# STM32MP21_CA35 register map
File version: 0.4
CPU: CM33 r0p1, little endian, MPU, FPU, vendor SysTick, 8 interrupt priority bits
Registers are 32-bit, read-write, reset 0x0 unless marked. A register's access mark holds for its fields unless they carry their own. Offsets are from the block's base; [hi:lo] are bit positions; lines under a group give offsets from that group; {n}, {i} and the like mark numbered series; 'fields as' and 'values as' point back to an identical list.

## DDRPHYC (part 1 of 2) — DDRPHYC address block description
Base 0x48C00000
Same registers: DDRPHYC_S 0x58C00000
{0x68+0x4000*i} DDRPHYC_ANIB{i}_MTESTMUXSEL (i=0..7) — DDRPHYC MtestMuxSel register
  [5:0] MTESTMUXSEL — Controls for the 64-1 mux for asynchronous data to the digital observation pin.
    0=Drives 0 from this chiplet (allows flat OR of pass-through information); 32=Drives 0 from PUB synthesized logic path into mux
{0x9C+0x4000*i} DDRPHYC_ANIB{i}_AFORCEDRVCONT (i=0..7) — DDRPHYC AForceDrvCont register
  [3:0] AFORCEDRVCONT — Forces continuous drive, per-lane, of the ACX4 instance controlled by this register.
{0xA0+0x4000*i} DDRPHYC_ANIB{i}_AFORCETRICONT (i=0..7) — DDRPHYC AForceTriCont register
  [3:0] AFORCETRICONT — Forces tristate control, per-lane, of the ACX4 instance controlled by this register.
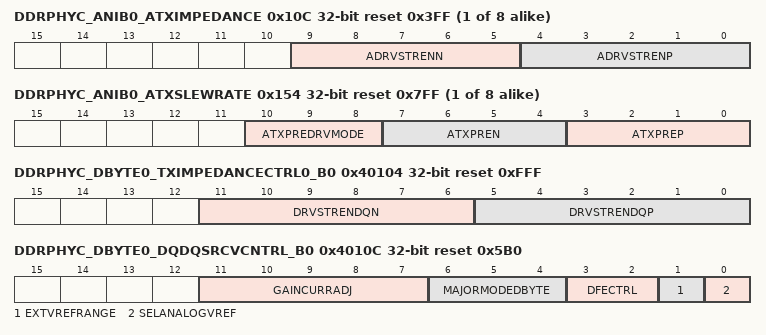
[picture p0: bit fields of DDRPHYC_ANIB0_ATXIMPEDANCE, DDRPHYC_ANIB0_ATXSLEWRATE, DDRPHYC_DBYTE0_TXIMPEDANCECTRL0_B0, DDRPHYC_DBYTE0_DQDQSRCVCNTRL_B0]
{0x10C+0x4000*i} DDRPHYC_ANIB{i}_ATXIMPEDANCE reset 0x3FF (i=0..7) — DDRPHYC address T{i} impedance control register
  [9:5] ADRVSTRENN — 5-bit bus used to select the target pull-down output impedance
    0=120; 1=60; 3=40; 7=30; 15=24; 31=20
  [4:0] ADRVSTRENP — 5-bit bus used to select the target pull-up output impedance
    0=120; 1=60; 3=40; 7=30; 15=24; 31=20
{0x14C+0x4000*i} DDRPHYC_ANIB{i}_ATESTPRBSERR ro reset not defined (i=0..7) — DDRPHYC ATestPrbsErr register
  [3:0] ATESTPRBSERR — Overall error indicator for each PRBS bump checker
{0x154+0x4000*i} DDRPHYC_ANIB{i}_ATXSLEWRATE reset 0x7FF (i=0..7) — DDRPHYC address T{i} slew rate and predriver control register
  [10:8] ATXPREDRVMODE — Controls predrivers to adjust timing of turn-on/-off of pull-up/-down segments.
  [7:4] ATXPREN — 4-bit binary trim for the driver pull-down slew rate
  [3:0] ATXPREP — 4-bit binary trim for the driver pull-up slew rate
{0x158+0x4000*i} DDRPHYC_ANIB{i}_ATESTPRBSERRCNT ro reset not defined (i=0..7) — DDRPHYC ATestPrbsErrCnt register
  [15:0] ATESTPRBSERRCNT — Overall error indicator for each PRBS bump checker
{0x200+0x4000*i} DDRPHYC_ANIB{i}_ATXDLY (i=0..7) — DDRPHYC ATxDly register
  [6:0] ATXDLY — Trained for LPDDR4 to generate timed address and command signals
0x40000 DDRPHYC_DBYTE0_DBYTEMISCMODE — DDRPHYC DBYTE module disable register
  [2] DBYTEDISABLE
    0=DBYTE enabled; 1=DBYTE disabled
0x40068 DDRPHYC_DBYTE0_MTESTMUXSEL — DDRPHYC MtestMuxSel register
  [5:0] MTESTMUXSEL — Controls for the 64-1 mux for asynchronous data to the digital observation pin.
    0=Drives 0 from this chiplet (allows flat 'OR' of pass-through information); 32=Drives 0 from PUB synthesized logic path into mux
0x40080 DDRPHYC_DBYTE0_DFIMRL reset 0x6 — DDRPHYC DFIMRL register
  [4:0] DFIMRL — DFI maximum read latency (MRL)
{0x40100+0x400*i} DDRPHYC_DBYTE0_VREFDAC0_R{i} (i=0..8) — DDRPHYC VrefDAC0_ry register
  [6:0] VREFDAC0 — PHY Rx Vless thansub>REFless than/sub> DAC control for rxdq cell internal Vless thansub>REFless than/sub>
0x40104 DDRPHYC_DBYTE0_TXIMPEDANCECTRL0_B0 reset 0xFFF — DDRPHYC data T0 impedance controls register
  [11:6] DRVSTRENDQN — 6-bit bus used to select the target pull-down output impedance
  [5:0] DRVSTRENDQP — 6-bit bus used to select the target pull-down output impedance
    0=HiZ; 1=480; 2=240; 3=160; 8=120; 9=96; 10=80; 11=68; 24=60; 25=53; 26=48; 27=43; 56=40; 57=36; 58=34; 59=32; 62=30; 63=28
0x4010C DDRPHYC_DBYTE0_DQDQSRCVCNTRL_B0 reset 0x5B0 — DDRPHYC DQ/DQS receiver control register
  [11:7] GAINCURRADJ — Adjusts gain current of RX amplifier stage.
  [6:4] MAJORMODEDBYTE — Selection of the major mode of operation for the receiver
    0=Input signal is terminated/referenced to Vless thansub>DDQless than/sub>/2 (or unterminated); 2=Input signal is terminated/referenced to Vless thansub>SSQ; 3=Input signal is terminated/referenced to Vless thansub>DDQless than/sub>
  [3:2] DFECTRL — Note: These settings are determined by PHY training firmware, and must not be overridden.
    0=DFE off; 1=DFE on; 2=Train DFE0 amplifier; 3=Train DFE1 amplifier
  [1] EXTVREFRANGE — Extends the range available in the local per-bit VREF generator.
  [0] SELANALOGVREF — Setting this bit forces the local per-bit Vless thansub>REFless than/sub> generator to pass the global VREFA
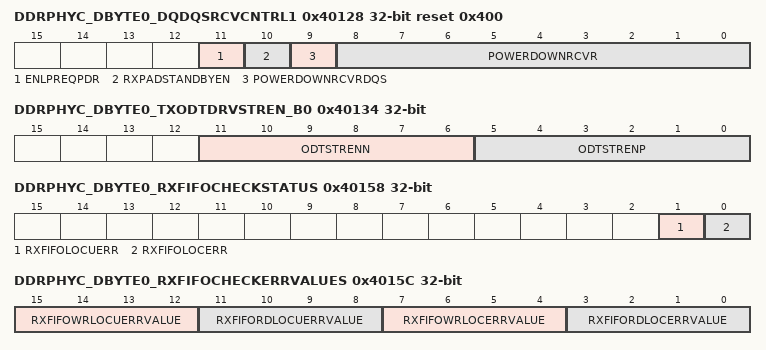
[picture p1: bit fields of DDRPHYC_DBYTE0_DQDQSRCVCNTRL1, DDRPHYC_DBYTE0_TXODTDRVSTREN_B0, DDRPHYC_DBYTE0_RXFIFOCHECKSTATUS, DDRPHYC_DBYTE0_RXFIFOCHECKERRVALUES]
0x40128 DDRPHYC_DBYTE0_DQDQSRCVCNTRL1 reset 0x400 — DDRPHYC DQ/DQS receiver control register
  [11] ENLPREQPDR — not used
  [10] RXPADSTANDBYEN — Enables rxdq/rxdqs Standby power savings, per pad-group.
  [9] POWERDOWNRCVRDQS — Active high signal which powers down the receiver
  [8:0] POWERDOWNRCVR — Active high signal which powers down the receiver
0x40130 DDRPHYC_DBYTE0_DQDQSRCVCNTRL2 — DDRPHYC DQ/DQS receiver control register
  [0] ENRXAGRESSIVEPDR
0x40134 DDRPHYC_DBYTE0_TXODTDRVSTREN_B0 — DDRPHYC TX ODT driver strength control register
  [11:6] ODTSTRENN — ODT pull-down impedance selection
  [5:0] ODTSTRENP — ODT pull-up impedance selection
0x40158 DDRPHYC_DBYTE0_RXFIFOCHECKSTATUS ro reset not defined — DDRPHYC status of RX FIFO consistency checks register
  [1] RXFIFOLOCUERR — If this bit is set, the read pointer (DFI side) on the read FIFO associated with data bits [7:4]
  [0] RXFIFOLOCERR — If this bit is set, the read pointer (DFI side) on the read FIFO associated with data bits [3:0]
0x4015C DDRPHYC_DBYTE0_RXFIFOCHECKERRVALUES ro reset not defined — DDRPHYC captured values associated with an RxFIFO consistency error register
  [15:12] RXFIFOWRLOCUERRVALUE — First error value captured for the write pointer (DQS side) on the read FIFO associated with data bits [7:4]
  [11:8] RXFIFORDLOCUERRVALUE — First error value captured for the read pointer (DFI side) on the read FIFO associated with data bits [7:4]
  [7:4] RXFIFOWRLOCERRVALUE — First error value captured for the write pointer (DQS side) on the read FIFO associated with data bits [3:0]
  [3:0] RXFIFORDLOCERRVALUE — First error value captured for the read pointer (DFI side) on the read FIFO associated with data bits [3:0]
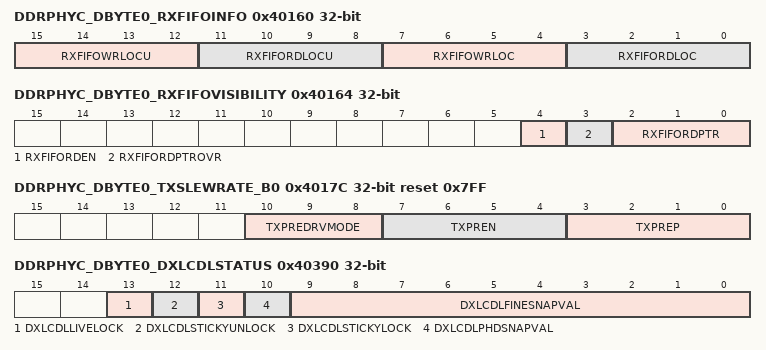
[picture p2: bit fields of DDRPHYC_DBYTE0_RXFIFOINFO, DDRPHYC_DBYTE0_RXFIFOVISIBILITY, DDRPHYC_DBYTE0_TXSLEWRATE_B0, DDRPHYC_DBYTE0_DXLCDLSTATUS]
0x40160 DDRPHYC_DBYTE0_RXFIFOINFO ro reset not defined — DDRPHYC data receive FIFO pointer values register
  [15:12] RXFIFOWRLOCU — Mission mode write pointer of the upper-nibble Rx FIFO
  [11:8] RXFIFORDLOCU — Mission mode read pointer of the upper-nibble Rx FIFO
  [7:4] RXFIFOWRLOC — Mission mode write pointer of the lower-nibble Rx FIFO
  [3:0] RXFIFORDLOC — Mission mode read pointer of the lower-nibble Rx FIFO
0x40164 DDRPHYC_DBYTE0_RXFIFOVISIBILITY — DDRPHYC R0 FIFO visibility register
  [4] RXFIFORDEN — Pulse [set 0-->1-->0] this bit to capture the FIFO contents.
  [3] RXFIFORDPTROVR — This bit is programmable as follows:
    0=Normal operation - Mission mode read pointer is enabled; 1=Override - Control of the Rx FIFO read pointer is ceded to this bit
  [2:0] RXFIFORDPTR — If RXFIFORDPTROVR is set, this bit field selects the Rx FIFO entry.
0x40168 DDRPHYC_DBYTE0_RXFIFOCONTENTSDQ3210 ro reset not defined — DDRPHYC R0 FIFO content DQ321x register
  [15:0] RXFIFOCONTENTSDQ3210 — Window into the contents of the Rx FIFO, as controlled
0x4016C DDRPHYC_DBYTE0_RXFIFOCONTENTSDQ7654 ro reset not defined — DDRPHYC R0 FIFO content DQ7654 register
  [15:0] RXFIFOCONTENTSDQ7654 — Window into the contents of the Rx FIFO as controlled
0x40170 DDRPHYC_DBYTE0_RXFIFOCONTENTSDBI ro reset not defined — DDRPHYC R0 FIFO content DBI register
  [3:0] RXFIFOCONTENTSDBI — Window into the contents of the Rx FIFO, as controlled
0x4017C DDRPHYC_DBYTE0_TXSLEWRATE_B0 reset 0x7FF — DDRPHYC T0 slew rate controls register
  [10:8] TXPREDRVMODE — Controls predrivers to adjust timing of turn-on and turn-off of pull-up and pull-down segments.
  [7:4] TXPREN — 4-bit binary trim for the driver pull -own slew rate
  [3:0] TXPREP — 4-bit binary trim for the driver pull-up slew rate
{0x401A0+0x400*i} DDRPHYC_DBYTE0_RXPBDLYTG0_R{i} (i=0..8) — DDRPHYC RxPBDlyTgx_r0 register
  [6:0] RXPBDLYTG0_R0 — Read DQ per-bit BDL delay (timing group 0)
{0x401A4+0x400*i} DDRPHYC_DBYTE0_RXPBDLYTG1_R{i} (i=0..8) — DDRPHYC RxPBDlyTg1_rx register
  [6:0] RXPBDLYTG1_R0 — Read DQ per-bit BDL delay (timing group 1)
0x40200 DDRPHYC_DBYTE0_RXENDLYTG0_U0 reset 0x100 — DDRPHYC RxEnDlyTgx_u0 register
  [10:0] RXENDLYTG0_U0 — Trained receive enable delay (timing group 0)
0x40204 DDRPHYC_DBYTE0_RXENDLYTG1_U0 reset 0x100 — DDRPHYC RxEnDlyTg1_ux register
  [10:0] RXENDLYTG1_U0 — Trained receive enable delay (timing group 1)
0x40230 DDRPHYC_DBYTE0_RXCLKDLYTG0_U0 reset 0x10 — DDRPHYC RxClkDlyTgx_u0 register
  [5:0] RXCLKDLYTG0_U0 — Trained read DQS to RxClk delay (timing group 0)
0x40234 DDRPHYC_DBYTE0_RXCLKDLYTG1_U0 reset 0x10 — DDRPHYC RxClkDlyTg1_ux register
  [5:0] RXCLKDLYTG1_U0 — Trained read DQS to RxClk delay (timing group 1)
0x40240 DDRPHYC_DBYTE0_RXCLKCDLYTG0_U0 reset 0x10 — DDRPHYC RxClkcDlyTgx_u0 register
  [5:0] RXCLKCDLYTG0_U0 — Trained read DQS_c to RxClkc delay (timing group 0)
0x40244 DDRPHYC_DBYTE0_RXCLKCDLYTG1_U0 reset 0x10 — DDRPHYC RxClkcDlyTg1_ux register
  [5:0] RXCLKCDLYTG1_U0 — Trained read DQS_c to RxClkc delay (timing group 1)
0x40280 DDRPHYC_DBYTE0_DQ0LNSEL — DDRPHYC DqLnSel register
  [2:0] DQYLNSEL — Supports mapping of PHY DQ to DRAM DQ within a byte (swizzle).
0x40284 DDRPHYC_DBYTE0_DQ1LNSEL reset 0x1 — DDRPHYC DqLnSel register
  fields as DDRPHYC_DBYTE0_DQ0LNSEL
0x40288 DDRPHYC_DBYTE0_DQ2LNSEL reset 0x2 — DDRPHYC DqLnSel register
  fields as DDRPHYC_DBYTE0_DQ0LNSEL
0x4028C DDRPHYC_DBYTE0_DQ3LNSEL reset 0x3 — DDRPHYC DqLnSel register
  fields as DDRPHYC_DBYTE0_DQ0LNSEL
0x40290 DDRPHYC_DBYTE0_DQ4LNSEL reset 0x4 — DDRPHYC DqLnSel register
  fields as DDRPHYC_DBYTE0_DQ0LNSEL
0x40294 DDRPHYC_DBYTE0_DQ5LNSEL reset 0x5 — DDRPHYC DqLnSel register
  fields as DDRPHYC_DBYTE0_DQ0LNSEL
0x40298 DDRPHYC_DBYTE0_DQ6LNSEL reset 0x6 — DDRPHYC DqLnSel register
  fields as DDRPHYC_DBYTE0_DQ0LNSEL
0x4029C DDRPHYC_DBYTE0_DQ7LNSEL reset 0x7 — DDRPHYC DqLnSel register
  fields as DDRPHYC_DBYTE0_DQ0LNSEL
{0x40300+0x400*i} DDRPHYC_DBYTE0_TXDQDLYTG0_R{i} reset 0x10 (i=0..8) — DDRPHYC TxDqDlyTgx_r0 register
  [8:0] TXDQDLYTG0_R0 — Write DQ delay (timing group 0)
{0x40304+0x400*i} DDRPHYC_DBYTE0_TXDQDLYTG1_R{i} reset 0x10 (i=0..8) — DDRPHYC TxDqDlyTg1_rx register
  [8:0] TXDQDLYTG1_R0 — Write DQ delay (timing group 1)
0x40340 DDRPHYC_DBYTE0_TXDQSDLYTG0_U0 reset 0x100 — DDRPHYC TxDqsDlyTgx_u0 register
  [9:0] TXDQSDLYTG0_U0 — Write DQS delay (timing group 0)
0x40344 DDRPHYC_DBYTE0_TXDQSDLYTG1_U0 reset 0x100 — DDRPHYC TxDqsDlyTg1_ux register
  [9:0] TXDQSDLYTG1_U0 — Write DQS delay (timing group 1)
0x40390 DDRPHYC_DBYTE0_DXLCDLSTATUS ro reset not defined — DDRPHYC debug status of the DBYTE LCDL register
  [13] DXLCDLLIVELOCK — Present value of whether the LCDL is locked
  [12] DXLCDLSTICKYUNLOCK — Latched value of whether the LCDL ever lost lock after the assertion of LCDLTSTENABLE
  [11] DXLCDLSTICKYLOCK — Latched value of whether the LCDL ever achieved lock after the assertion of LCDLTSTENABLE
  [10] DXLCDLPHDSNAPVAL — Value of the LCDL phase-detector output, latched by pulse
  [9:0] DXLCDLFINESNAPVAL — Value of the LCDL 1UI estimate code, latched by pulse on LcdlFineSnap while LCDLTSTENABLE = 1
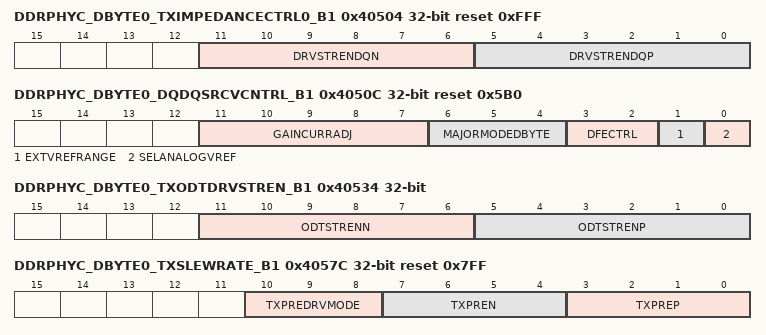
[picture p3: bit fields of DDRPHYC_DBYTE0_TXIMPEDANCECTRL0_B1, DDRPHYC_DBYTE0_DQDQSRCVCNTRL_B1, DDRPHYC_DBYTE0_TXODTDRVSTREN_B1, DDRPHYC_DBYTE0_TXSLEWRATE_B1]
0x40504 DDRPHYC_DBYTE0_TXIMPEDANCECTRL0_B1 reset 0xFFF — DDRPHYC data T0 impedance controls register
  fields as DDRPHYC_DBYTE0_TXIMPEDANCECTRL0_B0
0x4050C DDRPHYC_DBYTE0_DQDQSRCVCNTRL_B1 reset 0x5B0 — DDRPHYC DQ/DQS receiver control register
  fields as DDRPHYC_DBYTE0_DQDQSRCVCNTRL_B0
0x40534 DDRPHYC_DBYTE0_TXODTDRVSTREN_B1 — DDRPHYC TX ODT driver strength control register
  fields as DDRPHYC_DBYTE0_TXODTDRVSTREN_B0
0x4057C DDRPHYC_DBYTE0_TXSLEWRATE_B1 reset 0x7FF — DDRPHYC T0 slew rate controls register
  fields as DDRPHYC_DBYTE0_TXSLEWRATE_B0
0x40600 DDRPHYC_DBYTE0_RXENDLYTG0_U1 reset 0x100 — DDRPHYC RxEnDlyTgx_u1 register
  [10:0] RXENDLYTG0_U1 — Trained receive enable delay (timing group 0)
0x40604 DDRPHYC_DBYTE0_RXENDLYTG1_U1 reset 0x100 — DDRPHYC RxEnDlyTg1_u1 register
  [10:0] RXENDLYTG1_U1 — Trained receive enable delay (timing group 1)
0x40630 DDRPHYC_DBYTE0_RXCLKDLYTG0_U1 reset 0x10 — DDRPHYC RxClkDlyTgx_u1 register
  [5:0] RXCLKDLYTG0_U1 — Trained read DQS to RxClk delay (timing group 0)
0x40634 DDRPHYC_DBYTE0_RXCLKDLYTG1_U1 reset 0x10 — DDRPHYC RxClkDlyTg1_u1 register
  [5:0] RXCLKDLYTG1_U1 — Trained read DQS to RxClk delay (timing group 1)
0x40640 DDRPHYC_DBYTE0_RXCLKCDLYTG0_U1 reset 0x10 — DDRPHYC RxClkcDlyTgx_u1 register
  [5:0] RXCLKCDLYTG0_U1 — Trained read DQS_c to RxClkc delay (timing group 0)
0x40644 DDRPHYC_DBYTE0_RXCLKCDLYTG1_U1 reset 0x10 — DDRPHYC RxClkcDlyTg1_u1 register
  [5:0] RXCLKCDLYTG1_U1 — Trained read DQS_c to RxClkc delay (timing group 1)
0x40740 DDRPHYC_DBYTE0_TXDQSDLYTG0_U1 reset 0x100 — DDRPHYC TxDqsDlyTgx_u1 register
  [9:0] TXDQSDLYTG0_U1 — Write DQS delay (timing group 0)
0x40744 DDRPHYC_DBYTE0_TXDQSDLYTG1_U1 reset 0x100 — DDRPHYC TxDqsDlyTg1_u1 register
  [9:0] TXDQSDLYTG1_U1 — Write DQS delay (timing group 1)
0x44000 DDRPHYC_DBYTE1_DBYTEMISCMODE — DDRPHYC DBYTE module disable register
  [2] DBYTEDISABLE
    0=DBYTE enabled; 1=DBYTE disabled
0x44068 DDRPHYC_DBYTE1_MTESTMUXSEL — DDRPHYC MtestMuxSel register
  fields as DDRPHYC_DBYTE0_MTESTMUXSEL
0x44080 DDRPHYC_DBYTE1_DFIMRL reset 0x6 — DDRPHYC DFIMRL register
  [4:0] DFIMRL — DFI maximum read latency (MRL)
{0x44100+0x400*i} DDRPHYC_DBYTE1_VREFDAC0_R{i} (i=0..8) — DDRPHYC VrefDAC0_ry register
  fields as DDRPHYC_DBYTE0_VREFDAC0_R0
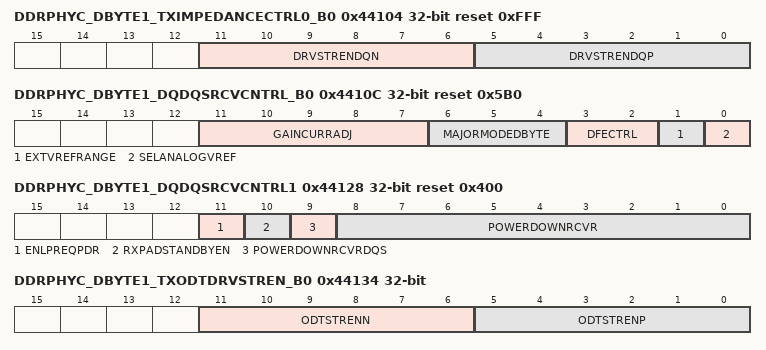
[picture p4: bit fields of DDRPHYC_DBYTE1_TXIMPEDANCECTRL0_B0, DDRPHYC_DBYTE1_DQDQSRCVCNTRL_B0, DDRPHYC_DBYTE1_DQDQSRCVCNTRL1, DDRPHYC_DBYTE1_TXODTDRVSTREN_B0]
0x44104 DDRPHYC_DBYTE1_TXIMPEDANCECTRL0_B0 reset 0xFFF — DDRPHYC data T1 impedance controls register
  fields as DDRPHYC_DBYTE0_TXIMPEDANCECTRL0_B0
0x4410C DDRPHYC_DBYTE1_DQDQSRCVCNTRL_B0 reset 0x5B0 — DDRPHYC DQ/DQS receiver control register
  fields as DDRPHYC_DBYTE0_DQDQSRCVCNTRL_B0
0x44128 DDRPHYC_DBYTE1_DQDQSRCVCNTRL1 reset 0x400 — DDRPHYC DQ/DQS receiver control register
  fields as DDRPHYC_DBYTE0_DQDQSRCVCNTRL1
0x44130 DDRPHYC_DBYTE1_DQDQSRCVCNTRL2 — DDRPHYC DQ/DQS receiver control register
  [0] ENRXAGRESSIVEPDR
0x44134 DDRPHYC_DBYTE1_TXODTDRVSTREN_B0 — DDRPHYC TX ODT driver strength control register
  fields as DDRPHYC_DBYTE0_TXODTDRVSTREN_B0
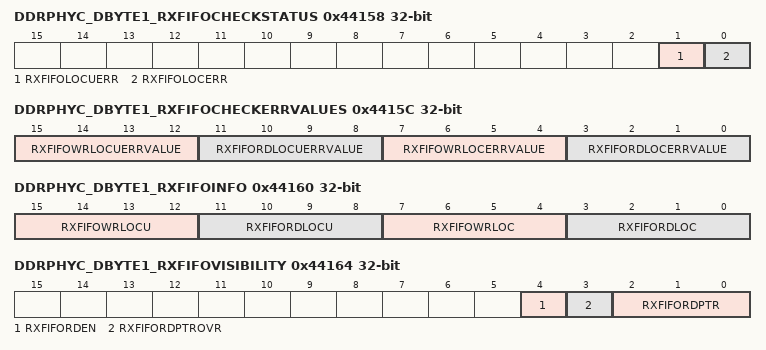
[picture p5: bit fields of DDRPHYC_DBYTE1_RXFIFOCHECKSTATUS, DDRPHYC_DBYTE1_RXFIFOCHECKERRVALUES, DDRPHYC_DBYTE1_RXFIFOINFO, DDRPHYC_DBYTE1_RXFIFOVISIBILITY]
0x44158 DDRPHYC_DBYTE1_RXFIFOCHECKSTATUS ro reset not defined — DDRPHYC status of RX FIFO consistency checks register
  fields as DDRPHYC_DBYTE0_RXFIFOCHECKSTATUS
0x4415C DDRPHYC_DBYTE1_RXFIFOCHECKERRVALUES ro reset not defined — DDRPHYC captured values associated with an RxFIFO consistency error register
  fields as DDRPHYC_DBYTE0_RXFIFOCHECKERRVALUES
0x44160 DDRPHYC_DBYTE1_RXFIFOINFO ro reset not defined — DDRPHYC data receive FIFO pointer values register
  fields as DDRPHYC_DBYTE0_RXFIFOINFO
0x44164 DDRPHYC_DBYTE1_RXFIFOVISIBILITY — DDRPHYC R1 FIFO visibility register
  fields as DDRPHYC_DBYTE0_RXFIFOVISIBILITY
0x44168 DDRPHYC_DBYTE1_RXFIFOCONTENTSDQ3210 ro reset not defined — DDRPHYC R1 FIFO content DQ321x register
  fields as DDRPHYC_DBYTE0_RXFIFOCONTENTSDQ3210
0x4416C DDRPHYC_DBYTE1_RXFIFOCONTENTSDQ7654 ro reset not defined — DDRPHYC R1 FIFO content DQ7654 register
  fields as DDRPHYC_DBYTE0_RXFIFOCONTENTSDQ7654
0x44170 DDRPHYC_DBYTE1_RXFIFOCONTENTSDBI ro reset not defined — DDRPHYC R1 FIFO content DBI register
  fields as DDRPHYC_DBYTE0_RXFIFOCONTENTSDBI
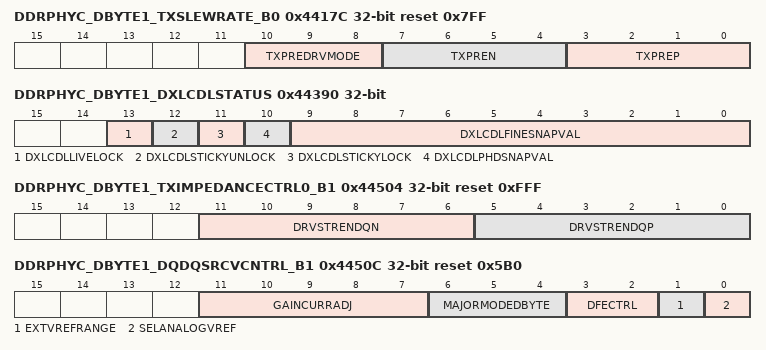
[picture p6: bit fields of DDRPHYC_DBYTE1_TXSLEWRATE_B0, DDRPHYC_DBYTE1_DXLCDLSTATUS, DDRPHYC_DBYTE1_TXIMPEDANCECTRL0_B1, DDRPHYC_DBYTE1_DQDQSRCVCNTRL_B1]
0x4417C DDRPHYC_DBYTE1_TXSLEWRATE_B0 reset 0x7FF — DDRPHYC T1 slew rate controls register
  fields as DDRPHYC_DBYTE0_TXSLEWRATE_B0
{0x441A0+0x400*i} DDRPHYC_DBYTE1_RXPBDLYTG0_R{i} (i=0..8) — DDRPHYC RxPBDlyTgx_r0 register
  [6:0] RXPBDLYTG0_R0 — Read DQ per-bit BDL delay (timing group 0)
{0x441A4+0x400*i} DDRPHYC_DBYTE1_RXPBDLYTG1_R{i} (i=0..8) — DDRPHYC RxPBDlyTg1_rx register
  [6:0] RXPBDLYTG1_R0 — Read DQ per-bit BDL delay (timing group 1)
0x44200 DDRPHYC_DBYTE1_RXENDLYTG0_U0 reset 0x100 — DDRPHYC RxEnDlyTgx_u0 register
  [10:0] RXENDLYTG0_U0 — Trained receive enable delay (timing group 0)
0x44204 DDRPHYC_DBYTE1_RXENDLYTG1_U0 reset 0x100 — DDRPHYC RxEnDlyTg1_ux register
  [10:0] RXENDLYTG1_U0 — Trained receive enable delay (timing group 1)
0x44230 DDRPHYC_DBYTE1_RXCLKDLYTG0_U0 reset 0x10 — DDRPHYC RxClkDlyTgx_u0 register
  fields as DDRPHYC_DBYTE0_RXCLKDLYTG0_U0
0x44234 DDRPHYC_DBYTE1_RXCLKDLYTG1_U0 reset 0x10 — DDRPHYC RxClkDlyTg1_ux register
  fields as DDRPHYC_DBYTE0_RXCLKDLYTG1_U0
0x44240 DDRPHYC_DBYTE1_RXCLKCDLYTG0_U0 reset 0x10 — DDRPHYC RxClkcDlyTgx_u0 register
  fields as DDRPHYC_DBYTE0_RXCLKCDLYTG0_U0
0x44244 DDRPHYC_DBYTE1_RXCLKCDLYTG1_U0 reset 0x10 — DDRPHYC RxClkcDlyTg1_ux register
  fields as DDRPHYC_DBYTE0_RXCLKCDLYTG1_U0
{0x44280+4i} DDRPHYC_DBYTE1_DQ{i}LNSEL reset 0x7 (i=0..7) — DDRPHYC DqLnSel register
  fields as DDRPHYC_DBYTE0_DQ0LNSEL
{0x44300+0x400*i} DDRPHYC_DBYTE1_TXDQDLYTG0_R{i} reset 0x10 (i=0..8) — DDRPHYC TxDqDlyTgx_r0 register
  [8:0] TXDQDLYTG0_R0 — Write DQ delay (timing group 0)
{0x44304+0x400*i} DDRPHYC_DBYTE1_TXDQDLYTG1_R{i} reset 0x10 (i=0..8) — DDRPHYC TxDqDlyTg1_rx register
  [8:0] TXDQDLYTG1_R0 — Write DQ delay (timing group 1)
0x44340 DDRPHYC_DBYTE1_TXDQSDLYTG0_U0 reset 0x100 — DDRPHYC TxDqsDlyTgx_u0 register
  [9:0] TXDQSDLYTG0_U0 — Write DQS delay (timing group 0)
0x44344 DDRPHYC_DBYTE1_TXDQSDLYTG1_U0 reset 0x100 — DDRPHYC TxDqsDlyTg1_ux register
  [9:0] TXDQSDLYTG1_U0 — Write DQS delay (timing group 1)
0x44390 DDRPHYC_DBYTE1_DXLCDLSTATUS ro reset not defined — DDRPHYC debug status of the DBYTE LCDL register
  fields as DDRPHYC_DBYTE0_DXLCDLSTATUS
0x44504 DDRPHYC_DBYTE1_TXIMPEDANCECTRL0_B1 reset 0xFFF — DDRPHYC data T1 impedance controls register
  fields as DDRPHYC_DBYTE0_TXIMPEDANCECTRL0_B0
0x4450C DDRPHYC_DBYTE1_DQDQSRCVCNTRL_B1 reset 0x5B0 — DDRPHYC DQ/DQS receiver control register
  fields as DDRPHYC_DBYTE0_DQDQSRCVCNTRL_B0
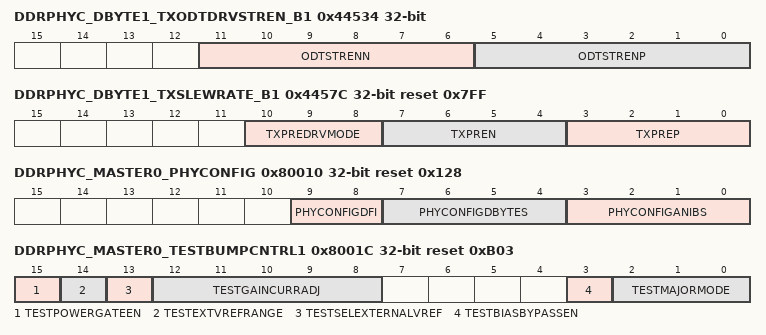
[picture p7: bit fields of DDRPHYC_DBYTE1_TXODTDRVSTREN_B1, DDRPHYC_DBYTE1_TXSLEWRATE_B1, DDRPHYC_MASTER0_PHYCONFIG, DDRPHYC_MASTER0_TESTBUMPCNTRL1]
0x44534 DDRPHYC_DBYTE1_TXODTDRVSTREN_B1 — DDRPHYC TX ODT driver strength control register
  fields as DDRPHYC_DBYTE0_TXODTDRVSTREN_B0
0x4457C DDRPHYC_DBYTE1_TXSLEWRATE_B1 reset 0x7FF — DDRPHYC T1 slew rate controls register
  fields as DDRPHYC_DBYTE0_TXSLEWRATE_B0
0x44600 DDRPHYC_DBYTE1_RXENDLYTG0_U1 reset 0x100 — DDRPHYC RxEnDlyTgx_u1 register
  [10:0] RXENDLYTG0_U1 — Trained receive enable delay (timing group 0)
0x44604 DDRPHYC_DBYTE1_RXENDLYTG1_U1 reset 0x100 — DDRPHYC RxEnDlyTg1_u1 register
  [10:0] RXENDLYTG1_U1 — Trained receive enable delay (timing group 1)
0x44630 DDRPHYC_DBYTE1_RXCLKDLYTG0_U1 reset 0x10 — DDRPHYC RxClkDlyTgx_u1 register
  fields as DDRPHYC_DBYTE0_RXCLKDLYTG0_U1
0x44634 DDRPHYC_DBYTE1_RXCLKDLYTG1_U1 reset 0x10 — DDRPHYC RxClkDlyTg1_u1 register
  fields as DDRPHYC_DBYTE0_RXCLKDLYTG1_U1
0x44640 DDRPHYC_DBYTE1_RXCLKCDLYTG0_U1 reset 0x10 — DDRPHYC RxClkcDlyTgx_u1 register
  fields as DDRPHYC_DBYTE0_RXCLKCDLYTG0_U1
0x44644 DDRPHYC_DBYTE1_RXCLKCDLYTG1_U1 reset 0x10 — DDRPHYC RxClkcDlyTg1_u1 register
  fields as DDRPHYC_DBYTE0_RXCLKCDLYTG1_U1
0x44740 DDRPHYC_DBYTE1_TXDQSDLYTG0_U1 reset 0x100 — DDRPHYC TxDqsDlyTgx_u1 register
  [9:0] TXDQSDLYTG0_U1 — Write DQS delay (timing group 0)
0x44744 DDRPHYC_DBYTE1_TXDQSDLYTG1_U1 reset 0x100 — DDRPHYC TxDqsDlyTg1_u1 register
  [9:0] TXDQSDLYTG1_U1 — Write DQS delay (timing group 1)
0x80000 DDRPHYC_MASTER0_RXFIFOINIT — DDRPHYC Rx FIFO pointer initialization control register
  [0] RXFIFOINITPTR — Setting this bit resets the PHY RXDATAFIFO read and write pointers.
0x80004 DDRPHYC_MASTER0_FORCECLKDISABLE — DDRPHYC ForceClkDisable register
  [3:0] FORCECLKDISABLE — This bit field forces the gating of MEMCLKs driven from the PHY.
0x8000C DDRPHYC_MASTER0_FORCEINTERNALUPDATE — DDRPHYC ForceInternalUpdate register
  [0] FORCEINTERNALUPDATE — Used by training firmware to force an internal PHY update event
0x80010 DDRPHYC_MASTER0_PHYCONFIG ro reset 0x128 — DDRPHYC read-only displays PHY configuration register
  [9:8] PHYCONFIGDFI — Returns the following value depending on the define:
  [7:4] PHYCONFIGDBYTES — Returns the following value depending on the define:
  [3:0] PHYCONFIGANIBS — Returns the following value depending on the define:
0x80014 DDRPHYC_MASTER0_PGCR — DDRPHYC PHY general configuration register
  [0] RXCLKRISEFALLMODE — Controls independent training for RxClk_c and RxClk_t.
    0=Independent training for RxClk_c and RxClk_t is disabled (default value); 1=Independent training for RxClk_c and RxClk_t is enabled
0x8001C DDRPHYC_MASTER0_TESTBUMPCNTRL1 reset 0xB03 — DDRPHYC test bump control1 register
  [15] TESTPOWERGATEEN — Do not use, for debug only
  [14] TESTEXTVREFRANGE — Setting this bit extends the VREF DAC range for debug.
  [13] TESTSELEXTERNALVREF — Do not use, for debug only
  [12:8] TESTGAINCURRADJ — Adjust gain and current of analog observe RX amplifier stage at analog test point.
  [3] TESTBIASBYPASSEN — Do not use, for debug only
  [2:0] TESTMAJORMODE — Selects the major mode of operation for the receiver.
    3=Setting for DDR4 systems to receive Alert_n
0x80020 DDRPHYC_MASTER0_CALUCLKINFO reset 0x320 — DDRPHYC impedance calibration clock ratio register
  [10:0] CALUCLKTICKSPER1US — Must be programmed to the number of DfiClks in 1 us (rounded up), with minimum value
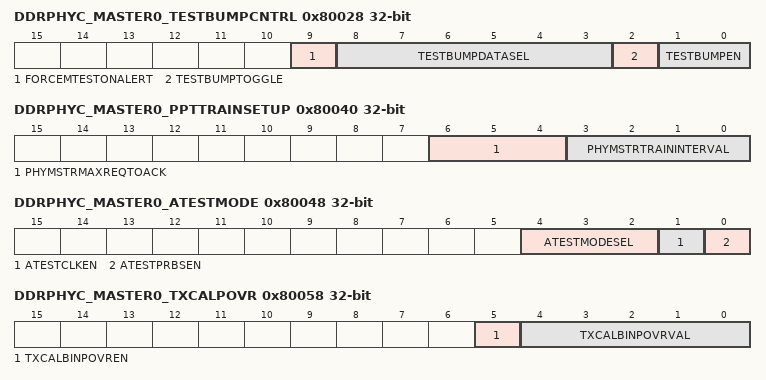
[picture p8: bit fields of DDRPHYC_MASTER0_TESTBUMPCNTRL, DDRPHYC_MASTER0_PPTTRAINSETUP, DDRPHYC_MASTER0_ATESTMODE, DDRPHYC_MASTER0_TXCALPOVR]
0x80028 DDRPHYC_MASTER0_TESTBUMPCNTRL — DDRPHYC test bump control register
  [9] FORCEMTESTONALERT — When set, this bit causes the digital observation output pin to be driven onto BP_ALERT_N.
  [8:3] TESTBUMPDATASEL — RVSD
  [2] TESTBUMPTOGGLE — Controls the output function of the signal.
    0=The output is tristate; 1=The output is selected by MtestMuxSel
  [1:0] TESTBUMPEN — Controls the output function of the signal BP_ALERT_N.
    0=High-z; 1=Pllout-divided-by-2, works up to full data rate; 2=PllDigTst[1], works up to 400 MHz; 3=PllDigTst[1], works up to 400 MHz
{0x8002C+4i} DDRPHYC_MASTER0_SEQ0BDLY{i} (i=0..3) — DDRPHYC Seq0BDLY{i} register
  [15:0] SEQ0BDLY{i} — PIE delay register {i}
0x8003C DDRPHYC_MASTER0_PHYALERTSTATUS ro reset not defined — DDRPHYC PHY alert status bit register
  [0] PHYALERT — Current state of ALERT_N
0x80040 DDRPHYC_MASTER0_PPTTRAINSETUP — DDRPHYC setup intervals for DFI PHY master operation register
  [6:4] PHYMSTRMAXREQTOACK — Max time from tdfi_phymstr_req asserted
    0=Disable PHY MASTER; {v}=Set tPHYMSTR_resp (v=1..6)
  [3:0] PHYMSTRTRAININTERVAL — Time between the end of one training, and the start
    0=Disable PHY MASTER; 1=PHY MASTER request interval = 524288 MEMCLKs; 2=PHY MASTER request interval = 1048576 MEMCLKs; 3=PHY MASTER request interval = 2097152 MEMCLKs; 4=PHY MASTER request interval = 4194304 MEMCLKs; 5=PHY MASTER request interval = 8388608 MEMCLKs; 6=PHY MASTER request interval = 16777216 MEMCLKs; 7=PHY MASTER request interval = 33554432 MEMCLKs; 8=PHY MASTER request interval = 67108864 MEMCLKs; 9=PHY MASTER request interval = 134217728 MEMCLKs; 10=PHY MASTER request interval = 268435456 MEMCLKs
0x80048 DDRPHYC_MASTER0_ATESTMODE — DDRPHYC ATestMode control register
  [4:2] ATESTMODESEL — Master mode select for ATest (loopback)
    0=Mission mode, all ATest disabled, loopback receivers powered down; 1=External loopback mode [Single data rate pattern - dfi_cas sent to all lanes]; 2=Internal loopback mode [Single data rate pattern]; 3=Internal loopback mode [Double data rate pattern]; 4=External loopback mode [Single data rate pattern - corresponding DFI signal sent to each lane]
  [1] ATESTCLKEN — Not used
  [0] ATESTPRBSEN — Enables loopback PRBS7 testing of all the DDR output pins.
0x80050 DDRPHYC_MASTER0_TXCALBINP ro reset not defined — DDRPHYC TxCalBinP register
  [4:0] TXCALBINP — Binary result of the 31-bit thermometer pull-up code
0x80054 DDRPHYC_MASTER0_TXCALBINN ro reset not defined — DDRPHYC TxCalBinN register
  [4:0] TXCALBINN — Binary result of the 31-bit thermometer pull-down code
0x80058 DDRPHYC_MASTER0_TXCALPOVR — DDRPHYC TX P impedance calibration override register
  [5] TXCALBINPOVREN
    1=Use the override value present in TxCalBinPOvrVal bit
  [4:0] TXCALBINPOVRVAL — Binary value which can override TXCALBINP bitfiled
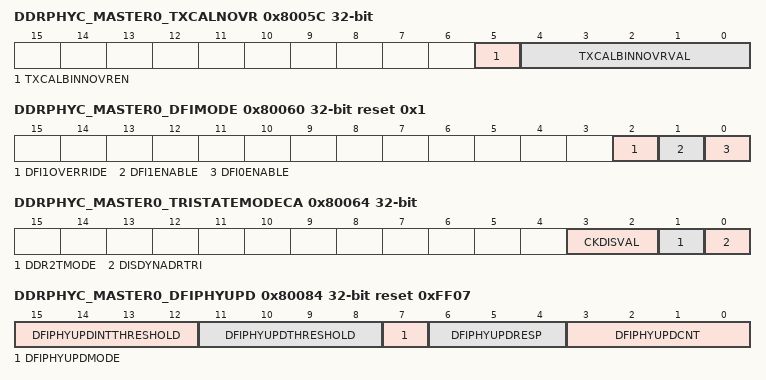
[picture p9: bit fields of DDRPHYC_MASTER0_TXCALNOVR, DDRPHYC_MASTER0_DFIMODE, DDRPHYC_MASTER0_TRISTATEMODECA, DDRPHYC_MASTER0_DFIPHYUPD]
0x8005C DDRPHYC_MASTER0_TXCALNOVR — DDRPHYC TX N impedance calibration override register
  [5] TXCALBINNOVREN
    1=Use the override value present in TXCALBINNOVRVAL bit field
  [4:0] TXCALBINNOVRVAL — Binary value which can override TXCALBINN bit field
0x80060 DDRPHYC_MASTER0_DFIMODE reset 0x1 — DDRPHYC enables for update and low-power interfaces for DFI0 and DFI1 register
  [2] DFI1OVERRIDE — Controls the PHY logic associated with both DFI0 and DFI1.
  [1] DFI1ENABLE — Enables operation for the PHY logic associated with DFI1.
  [0] DFI0ENABLE — Enables operation for the PHY logic associated with DFI0.
0x80064 DDRPHYC_MASTER0_TRISTATEMODECA — DDRPHYC mode select register for MEMCLK/address/command tristate register
  [3:2] CKDISVAL — The PHY provides four memory clocks (0 to 3).
  [1] DDR2TMODE — Must be set to 1 for dynamic tristate to work when CA bus is 2T or Geardown mode.
  [0] DISDYNADRTRI — When this bit is set, the dynamic tristate feature is disabled (on by default).
0x80068 DDRPHYC_MASTER0_MTESTMUXSEL — DDRPHYC MtestMuxSel register
  [5:0] MTESTMUXSEL — Controls for the 64-1 mux for asynchronous data to the digital observation pin.
    0=Drive 0 from this device (allows flat 'OR' of pass-through information); 32=Drive 0 from PUB synth logic path into mux
0x8006C DDRPHYC_MASTER0_MTESTPGMINFO — DDRPHYC MtestPgmInfo register
  [0] MTESTPGMINFO — This bit value can be driven onto the digital observation pin (no other hardware effect).
0x80070 DDRPHYC_MASTER0_DYNPWRDNUP — DDRPHYC dynamic power up/down control register
  [0] DYNPOWERDOWN
    1=Analog circuitry (voltage dacs, bias gen) is turned off; 0=Normal operation
0x80074 DDRPHYC_MASTER0_PMIENABLE — DDRPHYC PMIEnable register
  [0] PMIENABLE — This bit is dynamically written by PIE during frequency changes and must not be written by the user.
0x80078 DDRPHYC_MASTER0_PHYTID — DDRPHYC PhyTID register
  [15:0] PHYTID — Placeholder to store technology-specific information
0x80080 DDRPHYC_MASTER0_HWTMRL reset 0x6 — DDRPHYC HwtMRL register
  [4:0] HWTMRL — Master copy of MRL used by the PHY training firmware only
0x80084 DDRPHYC_MASTER0_DFIPHYUPD reset 0xFF07 — DDRPHYC DFI PhyUpdate request time counter register
  [15:12] DFIPHYUPDINTTHRESHOLD — Similar to DFIPHYUPDTHRESHOLD except that, rather than affecting the Phy update request, this bit field affects only the threshold used to generate the VT drift alarm interrupt.
  [11:8] DFIPHYUPDTHRESHOLD — - Nonzero codes are the threshold value for the change in the master LCDL 1UI phase code since the last Phy update request that triggers a new Phy update request;
    0=Disable threshold-based Phy update requests when DFIPHYUPDMODE = 0x1
  [7] DFIPHYUPDMODE
    0=Deterministic timer-based Phy update requests; 1=Non-deterministic threshold-based Phy update requests
  [6:4] DFIPHYUPDRESP — Enforces the t_phyupd_resp time (max time allowed to the controller to respond to the request for a PHY update).
    0=nMEMCLKs_phyupd_resp= 1024 MEMCLKs (default); 1=nMEMCLKs_phyupd_resp= 2048 MEMCLKs; 2=nMEMCLKs_phyupd_resp= 4096 MEMCLKs; 3=nMEMCLKs_phyupd_resp= 8192 MEMCLKs (not allowed in LPDDR4 mode)
  [3:0] DFIPHYUPDCNT — Controls the interval between the end of a PHY update transaction and a subsequent request.
    0=Disable timer-based PHY update when DFIPHYUPDMODE= 0; 1=16K MEMCLKs minus nMEMCLKs_phyupd_resp; 3=32K MEMCLKs minus nMEMCLKs_phyupd_resp; 7=64K MEMCLKs minus nMEMCLKs_phyupd_resp; 15=128K MEMCLKs minus nMEMCLKs_phyupd_resp
0x80088 DDRPHYC_MASTER0_PDAMRSWRITEMODE — DDRPHYC PdaMrsWriteMode register
  [0] PDAMRSWRITEMODE — Controls the write DQ generation per the timing requirements on DQ signals used for
0x8008C DDRPHYC_MASTER0_DFIGEARDOWNCTL — DDRPHYC DFIGEARDOWNCTL register
  [1:0] DFIGEARDOWNCTL — Bit[0] controls whether dfi_geardown_en causes chip-select (CS) timing to change.
    0=CKE timing is not dynamically modified with dfi_geardown_en; 1=CKE is delayed by an additional 1UI dynamically when dfi_geardown_en==1
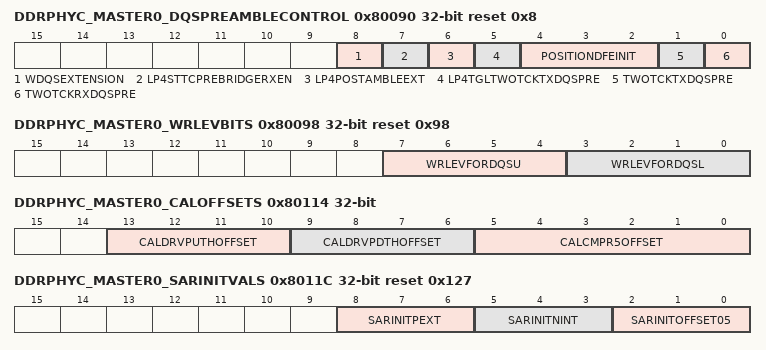
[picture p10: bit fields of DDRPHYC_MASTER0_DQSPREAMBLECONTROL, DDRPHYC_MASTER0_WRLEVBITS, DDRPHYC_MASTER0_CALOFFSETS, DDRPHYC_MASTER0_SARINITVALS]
0x80090 DDRPHYC_MASTER0_DQSPREAMBLECONTROL reset 0x8 — DDRPHYC control the PHY logic related to the read and write DQS preamble register
  [8] WDQSEXTENSION — When this bits is set, DQS_T and DQS_C are driven differentially to 0 and 1, respectively, before and after a write burst, except during a memory read transaction.
  [7] LP4STTCPREBRIDGERXEN — Used in LPDDR4 static-preamble mode to bridge the RxEn between two reads to the same timing group when the bubble is 1 memclk
  [6] LP4POSTAMBLEEXT — In LPDDR4 mode, this bit must be set to extend the write postamble.
    0=Half-memclk postamble, as in D4; 1=One-and-one-half-memclk postamble
  [5] LP4TGLTWOTCKTXDQSPRE — Used in LPDDR4 mode to modify the early preamble whenTwoTckTxDqsPre=1.
    0=Level first-memclk preamble; 1=Toggling first-memclk preamble
  [4:2] POSITIONDFEINIT — For DDR4 PHY, only when receive DFE is enabled
  [1] TWOTCKTXDQSPRE — For LPDDR4, all write operations are 2nCK such that this control must be set to 1.
  [0] TWOTCKRXDQSPRE — Widens the RxDqsEn window to allow larger drift in the incoming read DQS to take advantage of the larger/wider preamble generated by the DRAMs when D4 DRAMS are configured with DDR4 MR4 A11 read preamble = 1 for causing a 2nCK read preamble.
0x80094 DDRPHYC_MASTER0_MASTERX4CONFIG — DDRPHYC MasterX4Config register
  [3:0] X4TG — Set to 1 if this timing group/rank is x4 (as opposed to x8) memory.
0x80098 DDRPHYC_MASTER0_WRLEVBITS reset 0x98 — DDRPHYC write level feedback DQ observability selection register
  [7:4] WRLEVFORDQSU — DQ bit used for write levelization
    0=use DQ0; 7=use DQ7; 8=use |DQ[3:0]; 9=use |DQ[7:4]; 10=use |DQ[7:0]
  [3:0] WRLEVFORDQSL — DQ bit used for write levelization
    values as WRLEVFORDQSU
0x8009C DDRPHYC_MASTER0_ENABLECSMULTICAST — DDRPHYC EnableCsMulticast register
  [0] ENABLECSMULTICAST — Controls whether CS_N[3:2] must be multicast on CID[1:0] in DDR4 mode.
    0=Do not override pins corresponding to cid[1:0] (dfi_cid[1:0] connects to the pads); 1=Override pins corresponding to cid[1:0] with dfi_cs[3:2]
0x800B0 DDRPHYC_MASTER0_ACX4ANIBDIS — DDRPHYC Acx4AnibDis register
  [11:0] ACX4ANIBDIS — When a bit is set, the corresponding ACX nibble is disabled.
0x800B4 DDRPHYC_MASTER0_DMIPINPRESENT — DDRPHYC enable Read-DBI function in each DBYTE register
  [0] RDDBIENABLED — This bit must be set if Read-DBI is enabled in a connected DDR4 or LPDDR4 device.
0x800B8 DDRPHYC_MASTER0_ARDPTRINITVAL — DDRPHYC ARdPtrInitVal register
  [3:0] ARDPTRINITVAL — Initial pointer offset for the free-running FIFOs in the DBYTE
0x800E8 DDRPHYC_MASTER0_DBYTEDLLMODECNTRL — DDRPHYC DLL mode control for DBYTEs register
  [1] DLLRXPREAMBLEMODE — This bit must be set to 1 if read DQS preamble contains a toggle, for example DDR4 or LPDDR4 read toggling preamble mode.
0x80114 DDRPHYC_MASTER0_CALOFFSETS — IDDRPHYC impedance calibration offsets control register
  [13:10] CALDRVPUTHOFFSET — Adjusts the driver pull-up calibration code.
  [9:6] CALDRVPDTHOFFSET — Adjusts the driver pull-down calibration code.
  [5:0] CALCMPR5OFFSET — Adjusts the offset-compensated DAC code for the cmpana circuit at VREF == 0.
0x8011C DDRPHYC_MASTER0_SARINITVALS reset 0x127 — DDRPHYC SarInitVals register
  [8:6] SARINITPEXT — Specifies the SAR starting value for PEXT calibration.
  [5:3] SARINITNINT — Specifies the SAR starting value for NINT calibration.
  [2:0] SARINITOFFSET05 — Specifies the SAR starting value for OFFSET05 calibration.
0x80124 DDRPHYC_MASTER0_CALPEXTOVR — DDRPHYC CalPExtOvr register
  [4:0] CALPEXTOVR — If CALPEXTDIS is set, the value provided here by software is used instead of the automatically generated value which is visible via CalPExt field.
0x80128 DDRPHYC_MASTER0_CALCMPR5OVR — DDRPHYC CalCmpr5Ovr register
  [7:0] CALCMPR5OVR — If CALCMPR5DIS is set, the value provided here by software is used instead of the automatically generated value which is visible via CalCmpr5 field.
